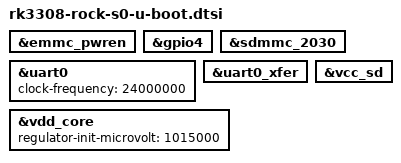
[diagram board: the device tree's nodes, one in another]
// SPDX-License-Identifier: GPL-2.0+

#include "rk3308-u-boot.dtsi"

&emmc_pwren {
	bootph-pre-ram;
	bootph-some-ram;
};

&gpio4 {
	bootph-pre-ram;
};

&sdmmc_2030 {
	bootph-pre-ram;
};

&uart0 {
	bootph-all;
	clock-frequency = <24000000>;
};

&uart0_xfer {
	bootph-all;
};

&vcc_sd {
	bootph-pre-ram;
};

&vdd_core {
	regulator-init-microvolt = <1015000>;
};
